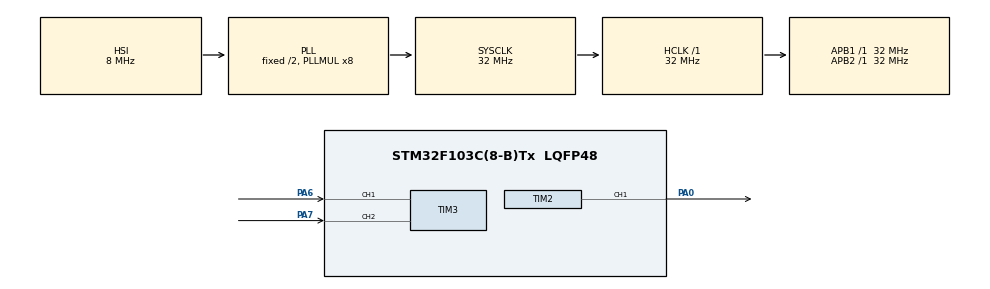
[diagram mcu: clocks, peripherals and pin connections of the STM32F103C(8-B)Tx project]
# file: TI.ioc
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Mcu.Family=STM32F1
Mcu.Name=STM32F103C(8-B)Tx
Mcu.Package=LQFP48
NVIC.PriorityGroup=NVIC_PRIORITYGROUP_4
PA0-WKUP.Signal=S_TIM2_CH1_ETR
PA13.Mode=Serial_Wire
PA13.Signal=SYS_JTMS-SWDIO
PA14.Mode=Serial_Wire
PA14.Signal=SYS_JTCK-SWCLK
PA6.Signal=S_TIM3_CH1
PA7.Signal=S_TIM3_CH2
ProjectManager.HeapSize=0x200
ProjectManager.StackSize=0x400
ProjectManager.TargetToolchain=MDK-ARM V5.32
RCC.AHBFreq_Value=32000000
RCC.APB1Freq_Value=32000000
RCC.APB1TimFreq_Value=32000000
RCC.APB2Freq_Value=32000000
RCC.APB2TimFreq_Value=32000000
RCC.HCLKFreq_Value=32000000
RCC.PLLMUL=RCC_PLL_MUL8
RCC.SYSCLKFreq_VALUE=32000000
RCC.SYSCLKSource=RCC_SYSCLKSOURCE_PLLCLK
RCC.USBFreq_Value=32000000
SH.S_TIM2_CH1_ETR.0=TIM2_CH1,PWM Generation1 CH1
SH.S_TIM3_CH1.0=TIM3_CH1,Encoder_Interface
SH.S_TIM3_CH2.0=TIM3_CH2,Encoder_Interface
TIM2.Channel-PWM\ Generation1\ CH1=TIM_CHANNEL_1
TIM2.Period=999
TIM2.Prescaler=71
TIM3.EncoderMode=TIM_ENCODERMODE_TI1
board=custom

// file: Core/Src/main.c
/* USER CODE BEGIN Header */
/**
  ******************************************************************************
  * @file           : main.c
  * @brief          : Main program body
  ******************************************************************************
  * @attention
  *
  * Copyright (c) 2026 STMicroelectronics.
  * All rights reserved.
  *
  * This software is licensed under terms that can be found in the LICENSE file
  * in the root directory of this software component.
  * If no LICENSE file comes with this software, it is provided AS-IS.
  *
  ******************************************************************************
  */
/* USER CODE END Header */
#include "main.h"

TIM_HandleTypeDef htim2;
TIM_HandleTypeDef htim3;

void SystemClock_Config(void);
static void MX_GPIO_Init(void);
static void MX_TIM3_Init(void);
static void MX_TIM2_Init(void);

/* USER CODE BEGIN 0 */
int16_t Encoder_Get(void)
{
	int16_t temp = __HAL_TIM_GET_COUNTER(&htim3);
	__HAL_TIM_SET_COUNTER(&htim3, 0);
	return temp;
}

// PWM控制电机（0~100%）
void Motor_SetPWM(int duty)
{
	if(duty > 100) duty = 100;
	if(duty < 0) duty = 0;

	__HAL_TIM_SET_COMPARE(&htim2, TIM_CHANNEL_1, duty * 10);
}

/* 全局变量 */
int16_t speed;  // 编码器速度
int pwm;        // 电机PWM

/* USER CODE END 0 */

int main(void)
{

  /* MCU Configuration--------------------------------------------------------*/

  /* Reset of all peripherals, Initializes the Flash interface and the Systick. */
  HAL_Init();

  /* Configure the system clock */
  SystemClock_Config();

  /* Initialize all configured peripherals */
  MX_GPIO_Init();
  MX_TIM3_Init();
  MX_TIM2_Init();
  /* USER CODE BEGIN 2 */
 HAL_TIM_Encoder_Start(&htim3, TIM_CHANNEL_ALL);
 HAL_TIM_PWM_Start(&htim2, TIM_CHANNEL_1);

  /* USER CODE END 2 */

  /* Infinite loop */
  while (1)
  {
    HAL_Delay(40);
	speed = Encoder_Get();
	 Motor_SetPWM(30);
  }
}

void SystemClock_Config(void)
{
  RCC_OscInitTypeDef RCC_OscInitStruct = {0};
  RCC_ClkInitTypeDef RCC_ClkInitStruct = {0};

  /** Initializes the RCC Oscillators according to the specified parameters
  * in the RCC_OscInitTypeDef structure.
  */
  RCC_OscInitStruct.OscillatorType = RCC_OSCILLATORTYPE_HSI;
  RCC_OscInitStruct.HSIState = RCC_HSI_ON;
  RCC_OscInitStruct.HSICalibrationValue = RCC_HSICALIBRATION_DEFAULT;
  RCC_OscInitStruct.PLL.PLLState = RCC_PLL_ON;
  RCC_OscInitStruct.PLL.PLLSource = RCC_PLLSOURCE_HSI_DIV2;
  RCC_OscInitStruct.PLL.PLLMUL = RCC_PLL_MUL8;
  if (HAL_RCC_OscConfig(&RCC_OscInitStruct) != HAL_OK)
  {
    Error_Handler();
  }

  /** Initializes the CPU, AHB and APB buses clocks
  */
  RCC_ClkInitStruct.ClockType = RCC_CLOCKTYPE_HCLK|RCC_CLOCKTYPE_SYSCLK
                              |RCC_CLOCKTYPE_PCLK1|RCC_CLOCKTYPE_PCLK2;
  RCC_ClkInitStruct.SYSCLKSource = RCC_SYSCLKSOURCE_PLLCLK;
  RCC_ClkInitStruct.AHBCLKDivider = RCC_SYSCLK_DIV1;
  RCC_ClkInitStruct.APB1CLKDivider = RCC_HCLK_DIV1;
  RCC_ClkInitStruct.APB2CLKDivider = RCC_HCLK_DIV1;

  if (HAL_RCC_ClockConfig(&RCC_ClkInitStruct, FLASH_LATENCY_1) != HAL_OK)
  {
    Error_Handler();
  }
}

static void MX_TIM2_Init(void)
{

  TIM_MasterConfigTypeDef sMasterConfig = {0};
  TIM_OC_InitTypeDef sConfigOC = {0};

  htim2.Instance = TIM2;
  htim2.Init.Prescaler = 71;
  htim2.Init.CounterMode = TIM_COUNTERMODE_UP;
  htim2.Init.Period = 999;
  htim2.Init.ClockDivision = TIM_CLOCKDIVISION_DIV1;
  htim2.Init.AutoReloadPreload = TIM_AUTORELOAD_PRELOAD_DISABLE;
  if (HAL_TIM_PWM_Init(&htim2) != HAL_OK)
  {
    Error_Handler();
  }
  sMasterConfig.MasterOutputTrigger = TIM_TRGO_RESET;
  sMasterConfig.MasterSlaveMode = TIM_MASTERSLAVEMODE_DISABLE;
  if (HAL_TIMEx_MasterConfigSynchronization(&htim2, &sMasterConfig) != HAL_OK)
  {
    Error_Handler();
  }
  sConfigOC.OCMode = TIM_OCMODE_PWM1;
  sConfigOC.Pulse = 0;
  sConfigOC.OCPolarity = TIM_OCPOLARITY_HIGH;
  sConfigOC.OCFastMode = TIM_OCFAST_DISABLE;
  if (HAL_TIM_PWM_ConfigChannel(&htim2, &sConfigOC, TIM_CHANNEL_1) != HAL_OK)
  {
    Error_Handler();
  }
  HAL_TIM_MspPostInit(&htim2);

}

static void MX_TIM3_Init(void)
{

  TIM_Encoder_InitTypeDef sConfig = {0};
  TIM_MasterConfigTypeDef sMasterConfig = {0};

  htim3.Instance = TIM3;
  htim3.Init.Prescaler = 0;
  htim3.Init.CounterMode = TIM_COUNTERMODE_UP;
  htim3.Init.Period = 65535;
  htim3.Init.ClockDivision = TIM_CLOCKDIVISION_DIV1;
  htim3.Init.AutoReloadPreload = TIM_AUTORELOAD_PRELOAD_DISABLE;
  sConfig.EncoderMode = TIM_ENCODERMODE_TI1;
  sConfig.IC1Polarity = TIM_ICPOLARITY_RISING;
  sConfig.IC1Selection = TIM_ICSELECTION_DIRECTTI;
  sConfig.IC1Prescaler = TIM_ICPSC_DIV1;
  sConfig.IC1Filter = 0;
  sConfig.IC2Polarity = TIM_ICPOLARITY_RISING;
  sConfig.IC2Selection = TIM_ICSELECTION_DIRECTTI;
  sConfig.IC2Prescaler = TIM_ICPSC_DIV1;
  sConfig.IC2Filter = 0;
  if (HAL_TIM_Encoder_Init(&htim3, &sConfig) != HAL_OK)
  {
    Error_Handler();
  }
  sMasterConfig.MasterOutputTrigger = TIM_TRGO_RESET;
  sMasterConfig.MasterSlaveMode = TIM_MASTERSLAVEMODE_DISABLE;
  if (HAL_TIMEx_MasterConfigSynchronization(&htim3, &sMasterConfig) != HAL_OK)
  {
    Error_Handler();
  }

}

static void MX_GPIO_Init(void)
{

  /* GPIO Ports Clock Enable */
  __HAL_RCC_GPIOA_CLK_ENABLE();

}

void Error_Handler(void)
{
  __disable_irq();
  while (1)
  {
  }
}
